# apollo510 register map
Vendor: Ambiq Micro; Series: Apollo; File version: 1.0
CPU: CM55 r1p1, little endian, MPU, FPU, double-precision FPU, DSP, I-cache, D-cache, VTOR, ITCM, DTCM, 4 interrupt priority bits, 0 interrupts, 8 SAU regions
Registers are 32-bit, read-write, reset 0x0 unless marked. A register's access mark holds for its fields unless they carry their own. Offsets are from the block's base; [hi:lo] are bit positions; {n}, {i} and the like mark numbered series; 'fields as' and 'values as' point back to an identical list.

## MCUCTRL (part 2 of 2) — MCU Miscellaneous Control Logic
Base 0x40020000
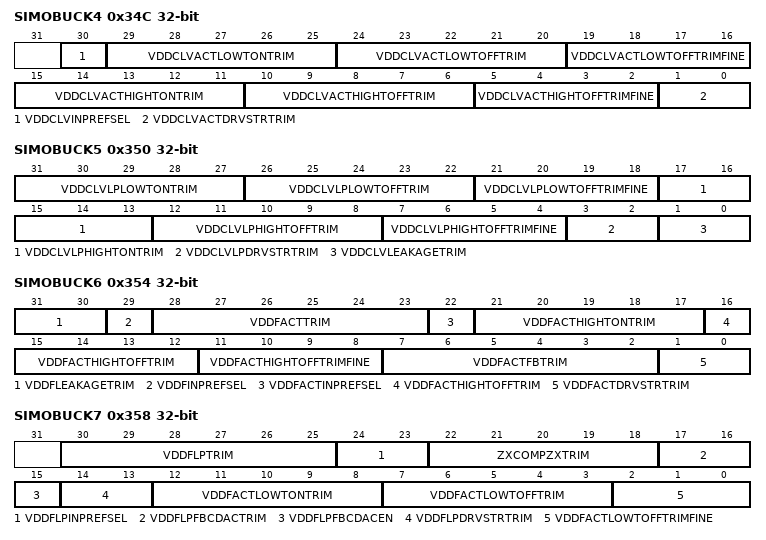
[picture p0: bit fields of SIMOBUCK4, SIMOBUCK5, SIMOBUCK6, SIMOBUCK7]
0x34C SIMOBUCK4 — SIMO Buck Muxed VDDC LV Active Sequence Trim Control
  [30] VDDCLVINPREFSEL — DEPRECATED
  [29:25] VDDCLVACTLOWTONTRIM — VDDC LV active low ton trim control for Buck sequence.
  [24:20] VDDCLVACTLOWTOFFTRIM — VDDC LV active low trim control for a 500 MHz clock inside the simobuck analog design.
  [19:16] VDDCLVACTLOWTOFFTRIMFINE — DEPRECATED.
  [15:11] VDDCLVACTHIGHTONTRIM — VDDC LV active high ton trim control for Buck sequence.
  [10:6] VDDCLVACTHIGHTOFFTRIM — VDDC LV active high toff trim control for Buck sequence.
  [5:2] VDDCLVACTHIGHTOFFTRIMFINE — DEPRECATED.
  [1:0] VDDCLVACTDRVSTRTRIM — VDDC LV active trim control for drive strength.
0x350 SIMOBUCK5 — SIMO Buck Muxed VDDC LV Low PowerSequence Trim Control
  [31:27] VDDCLVLPLOWTONTRIM — VDDC LV low power high ton trim control for Buck sequence.
  [26:22] VDDCLVLPLOWTOFFTRIM — VDDC LV low power low toff trim control for Buck sequence.
  [21:18] VDDCLVLPLOWTOFFTRIMFINE — DEPRECATED.
  [17:13] VDDCLVLPHIGHTONTRIM — VDDC LV low power high ton trim control for Buck sequence.
  [12:8] VDDCLVLPHIGHTOFFTRIM — VDDC LV low power high toff trim control for Buck sequence.
  [7:4] VDDCLVLPHIGHTOFFTRIMFINE — DEPRECATED.
  [3:2] VDDCLVLPDRVSTRTRIM — VDDC LV low power trim control for drive strength.
  [1:0] VDDCLVLEAKAGETRIM — DEPRECATED
0x354 SIMOBUCK6 — SIMO Buck Muxed VDDF Active Sequence Trim Control
  [31:30] VDDFLEAKAGETRIM — DEPRECATED
  [29] VDDFINPREFSEL — DEPRECATED
  [28:23] VDDFACTTRIM — VDDF active trim.
  [22] VDDFACTINPREFSEL — DEPRECATED
  [21:17] VDDFACTHIGHTONTRIM — VDDF active high ton trim control for Buck sequence.
  [16:12] VDDFACTHIGHTOFFTRIM — VDDF active high toff trim control for Buck sequence.
  [11:8] VDDFACTHIGHTOFFTRIMFINE — DEPRECATED.
  [7:2] VDDFACTFBTRIM — DEPRECATED
  [1:0] VDDFACTDRVSTRTRIM — VDDF active high toff trim for drive strength.
0x358 SIMOBUCK7 — SIMO Buck Muxed VDDF active Sequence Trim Control
  [30:25] VDDFLPTRIM — VDDF low power trim.
  [24:23] VDDFLPINPREFSEL — DEPRECATED
  [22:18] ZXCOMPZXTRIM — Zxcomp trim. Feedthrough to analog.
  [17:16] VDDFLPFBCDACTRIM — DEPRECATED
  [15] VDDFLPFBCDACEN — DEPRECATED
  [14:13] VDDFLPDRVSTRTRIM — VDDF active trim control for drive strength.
  [12:8] VDDFACTLOWTONTRIM — VDDF active low ton trim control for Buck sequence.
  [7:3] VDDFACTLOWTOFFTRIM — VDDF active low toff trim control for Buck sequence.
  [2:0] VDDFACTLOWTOFFTRIMFINE — DEPRECATED.
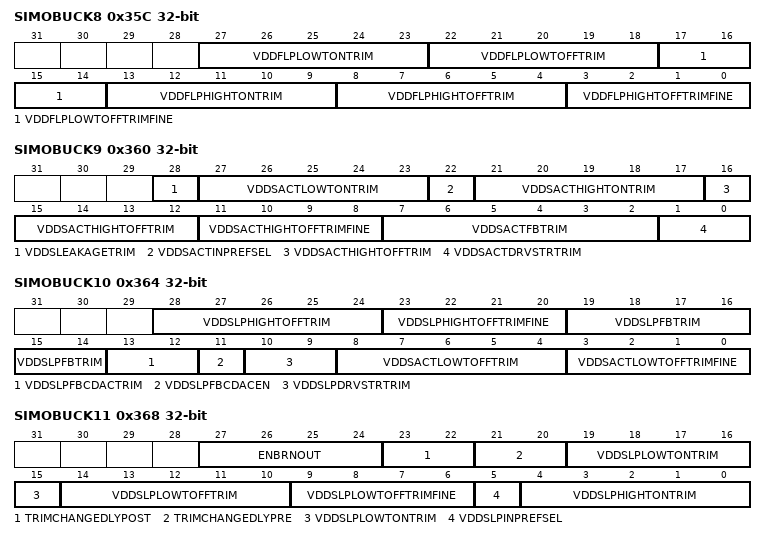
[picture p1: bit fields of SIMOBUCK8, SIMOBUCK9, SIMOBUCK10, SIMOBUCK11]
0x35C SIMOBUCK8 — SIMO Buck Muxed VDDF Low Power Sequence Trim Control
  [27:23] VDDFLPLOWTONTRIM — VDDF low power low ton trim control for Buck sequence.
  [22:18] VDDFLPLOWTOFFTRIM — VDDF low power low toff trim control for Buck sequence.
  [17:14] VDDFLPLOWTOFFTRIMFINE — DEPRECATED.
  [13:9] VDDFLPHIGHTONTRIM — VDDF low power high ton trim control for Buck sequence.
  [8:4] VDDFLPHIGHTOFFTRIM — VDDF low power high toff trim control for Buck sequence.
  [3:0] VDDFLPHIGHTOFFTRIMFINE — DEPRECATED.
0x360 SIMOBUCK9 — SIMO Buck Muxed VDDS Active Sequence Trim Control
  [28] VDDSLEAKAGETRIM — DEPRECATED
  [27:23] VDDSACTLOWTONTRIM — VDDS active low ton trim control for Buck sequence.
  [22] VDDSACTINPREFSEL — DEPRECATED
  [21:17] VDDSACTHIGHTONTRIM — VDDS active high ton trim control for Buck sequence.
  [16:12] VDDSACTHIGHTOFFTRIM — VDDS active high toff trim control for Buck sequence.
  [11:8] VDDSACTHIGHTOFFTRIMFINE — DEPRECATED.
  [7:2] VDDSACTFBTRIM — DEPRECATED
  [1:0] VDDSACTDRVSTRTRIM — simobuck_vdds_act_drvstr_trim
0x364 SIMOBUCK10 — SIMO Buck Muxed VDDS active Sequence Trim Control
  [28:24] VDDSLPHIGHTOFFTRIM — VDDS low power high toff trim control for a Buck sequence.
  [23:20] VDDSLPHIGHTOFFTRIMFINE — DEPRECATED.
  [19:14] VDDSLPFBTRIM — DEPRECATED
  [13:12] VDDSLPFBCDACTRIM — DEPRECATED
  [11] VDDSLPFBCDACEN — DEPRECATED
  [10:9] VDDSLPDRVSTRTRIM — VDDS low power trim control for drive strength.
  [8:4] VDDSACTLOWTOFFTRIM — VDDS active low toff trim control for Buck sequence.
  [3:0] VDDSACTLOWTOFFTRIMFINE — DEPRECATED.
0x368 SIMOBUCK11 — SIMO Buck Muxed Sequence Trim Control
  [27:24] ENBRNOUT — Enable each individual rail counter.
  [23:22] TRIMCHANGEDLYPOST — Delay used on the trims valid assertion after trims are changed.
  [21:20] TRIMCHANGEDLYPRE — Delay used on the trims valid de-assertion before trims are changed.
  [19:15] VDDSLPLOWTONTRIM — VDDS low power low ton trim control for a Buck sequence.
  [14:10] VDDSLPLOWTOFFTRIM — VDDS low power low toff trim control for a Buck sequence.
  [9:6] VDDSLPLOWTOFFTRIMFINE — DEPRECATED.
  [5] VDDSLPINPREFSEL — DEPRECATED
  [4:0] VDDSLPHIGHTONTRIM — VDDS low power high ton trim control for a Buck sequence.
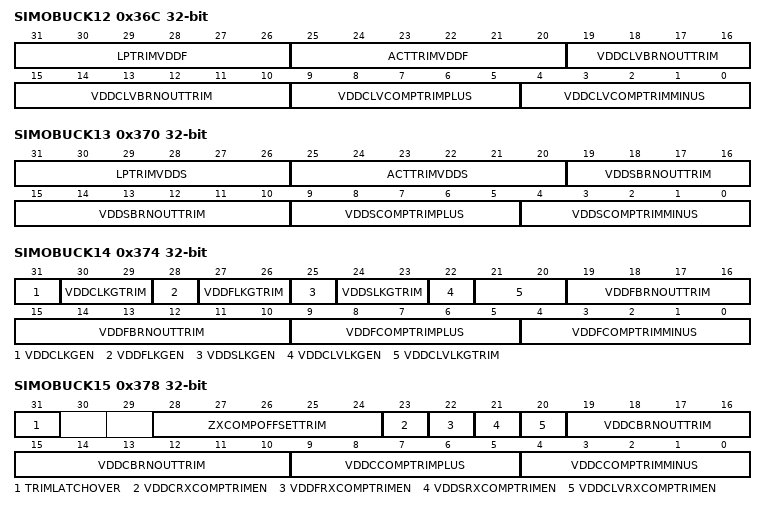
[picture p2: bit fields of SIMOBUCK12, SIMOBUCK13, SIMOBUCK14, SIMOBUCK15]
0x36C SIMOBUCK12 — SIMO Buck Compare, Brown out, Active, Low power Trim Control
  [31:26] LPTRIMVDDF — Low power VDDF trim.
  [25:20] ACTTRIMVDDF — Active VDDF trim.
  [19:10] VDDCLVBRNOUTTRIM — Digital brown out max counter value for VDDC LV rail.
  [9:5] VDDCLVCOMPTRIMPLUS — Static trim to allow separation when low power GT active rail.
  [4:0] VDDCLVCOMPTRIMMINUS — Static trim to allow separation between low power and active rail.
0x370 SIMOBUCK13 — SIMO Buck Compare, Brown out, Active, Low power Trim Control
  [31:26] LPTRIMVDDS — Low power VDDS trim.
  [25:20] ACTTRIMVDDS — Active VDDS trim.
  [19:10] VDDSBRNOUTTRIM — Digital brown out max counter value for VDDS rail.
  [9:5] VDDSCOMPTRIMPLUS — Static trim to allow separation when low power GT active rail.
  [4:0] VDDSCOMPTRIMMINUS — Static trim to allow separation between low power and active rail.
0x374 SIMOBUCK14 — SIMO Buck Compare, Brown out, Active, Low power and Leakage Trim Control
  [31] VDDCLKGEN — Leakage vddc rail enable. Set before simobuck comes up.
  [30:29] VDDCLKGTRIM — Leakage trim for vddc.
  [28] VDDFLKGEN — Leakage vddf rail enable. Set before simobuck comes up.
  [27:26] VDDFLKGTRIM — Leakage trim for vddf.
  [25] VDDSLKGEN — Leakage vdds rail enable. Set before simobuck comes up.
  [24:23] VDDSLKGTRIM — Leakage trim for vdds.
  [22] VDDCLVLKGEN — Leakage vddc lv rail enable. Set before simobuck comes up.
  [21:20] VDDCLVLKGTRIM — Leakage trim for vddc lv.
  [19:10] VDDFBRNOUTTRIM — Digital Brown out max counter value for VDDF rail.
  [9:5] VDDFCOMPTRIMPLUS — Static trim to allow separation when low power GT active rail.
  [4:0] VDDFCOMPTRIMMINUS — Static trim to allow separation between low power and active rail.
0x378 SIMOBUCK15 — SIMO Buck Compare, Brown out, Active and Low power Trim Control
  [31] TRIMLATCHOVER — Override / Bypass the simobuck trim latch to enable on-the-fly trimming for VDDF and VDDS active and LP trims
  [28:24] ZXCOMPOFFSETTRIM — Zxcomp offset trim. Feedthrough to analog.
  [23] VDDCRXCOMPTRIMEN — Enable the VDDC rail. If not enabled, the rail will not be regulated. This must be done before simobuck comes up.
  [22] VDDFRXCOMPTRIMEN — Enable the VDDF rail. If not enabled, the rail will not be regulated. This must be done before simobuck comes up.
  [21] VDDSRXCOMPTRIMEN — Enable the VDDS rail. If not enabled, the rail will not be regulated. This must be done before simobuck comes up.
  [20] VDDCLVRXCOMPTRIMEN — Enable the VDDC LV rail. If not enabled, the rail will not be regulated. This must be done before simobuck comes up.
  [19:10] VDDCBRNOUTTRIM — Digital brown out max counter value for VDDC rail.
  [9:5] VDDCCOMPTRIMPLUS — Static trim to allow separation when low power GT active rail.
  [4:0] VDDCCOMPTRIMMINUS — Static trim to allow separation between low power and active rail.
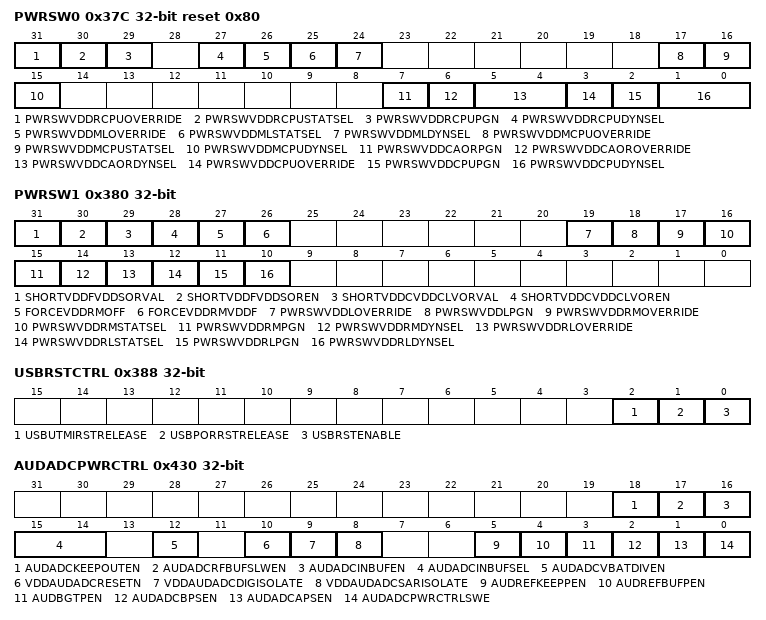
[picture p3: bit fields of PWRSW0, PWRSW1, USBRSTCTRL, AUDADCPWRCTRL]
0x37C PWRSW0 reset 0x80 — PWRSW Control 0
  [31] PWRSWVDDRCPUOVERRIDE — override enable for pwrsw_vddrcpu_dynsel and pgn
  [30] PWRSWVDDRCPUSTATSEL — VDDRCPU power switch static select
    1=VDDFLP (Select VDDFLP rail); 0=VDDS (Select VDDS rail)
  [29] PWRSWVDDRCPUPGN — override value for pwrsw_vddrcpu_pgn
  [27] PWRSWVDDRCPUDYNSEL — override value for pwrsw_vddrcpu_dynsel
  [26] PWRSWVDDMLOVERRIDE — override enable for pwrsw_vddml_dynsel
  [25] PWRSWVDDMLSTATSEL — VDDML power switch static select
    0=VDDC (Select VDDC rail); 1=VDDF (Select VDDF rail)
  [24] PWRSWVDDMLDYNSEL — override value for pwrsw_vddml_dynsel
  [17] PWRSWVDDMCPUOVERRIDE — override enable for pwrsw_vddmcpu_dynsel
  [16] PWRSWVDDMCPUSTATSEL — VDDMCPU power switch static select
    0=VDDC (Select VDDC rail); 1=VDDF (Select VDDF rail)
  [15] PWRSWVDDMCPUDYNSEL — override value for pwrsw_vddmcpu_dynsel
  [7] PWRSWVDDCAORPGN — override enable for pwrsw_vddcaor_pgn
  [6] PWRSWVDDCAOROVERRIDE — override enable for pwrsw_vddcaor_dynsel
  [5:4] PWRSWVDDCAORDYNSEL — override value for pwrsw_vddcaor_dynsel
  [3] PWRSWVDDCPUOVERRIDE — override enable for pwrsw_vddcpu_dynsel and pgn
  [2] PWRSWVDDCPUPGN — override value for pwrsw_vddcpu_pgn
  [1:0] PWRSWVDDCPUDYNSEL — override value for pwrsw_vddcpu_dynsel
0x380 PWRSW1 — PWRSW Control 1
  [31] SHORTVDDFVDDSORVAL — pwrsw short override value for vddf/vdds
  [30] SHORTVDDFVDDSOREN — pwrsw short override select for vddf/vdds
  [29] SHORTVDDCVDDCLVORVAL — pwrsw short override value for vddc/vddclv
  [28] SHORTVDDCVDDCLVOREN — pwrsw short override select for vddc/vddclv
  [27] FORCEVDDRMOFF — Setting this bit forces VDDRM to be open when Flash is off. This is valid for only normal operational mode (i.e. without overrides).
  [26] FORCEVDDRMVDDF — Setting this bit selects VDDF for VDDRM when Flash is off. This is valid for only normal operational mode (i.e. without overrides).
  [19] PWRSWVDDLOVERRIDE — override enable for pwrsw_vddl_pgn
  [18] PWRSWVDDLPGN — override value for pwrsw_vddl_pgn
  [17] PWRSWVDDRMOVERRIDE — override enable for pwrsw_vddrm_dynsel and pgn
  [16] PWRSWVDDRMSTATSEL — VDDRM power switch static select
    1=VDDFLP (Select VDDFLP rail); 0=VDDS (Select VDDS rail)
  [15] PWRSWVDDRMPGN — override value for pwrsw_vddrm_pgn
  [14] PWRSWVDDRMDYNSEL — override value for pwrsw_vddrm_dynsel
  [13] PWRSWVDDRLOVERRIDE — override enable for pwrsw_vddrl_dynsel and pgn
  [12] PWRSWVDDRLSTATSEL — VDDRL power switch static select
    1=VDDFLP (Select VDDFLP rail); 0=VDDS (Select VDDS rail)
  [11] PWRSWVDDRLPGN — override value for pwrsw_vddrl_pgn
  [10] PWRSWVDDRLDYNSEL — override value for pwrsw_vddrl_dynsel
0x388 USBRSTCTRL — USB Reset Startup Control
  [2] USBUTMIRSTRELEASE — Set this bit to '1' after USB power domain is up. This will release the reset override condition
  [1] USBPORRSTRELEASE — Set this bit to '1' after USB power domain is up. This will release the reset override condition
  [0] USBRSTENABLE — This bit enables this register control. If set to '1', the reset release bits will be active. If set to '0', this register is not controlling the USB override bits.
{0x3A8+4i} FLASHWPROT{i} (i=0..3) — These bits write-protect flash in 16KB chunks, but cpu still can excute from that that memory.
  [31:0] FW{i}BITS — Write protect flash {0x0+0x80000*i} - {0x7FFFF+0x80000*i}. Each bit provides write protection for 16KB chunks of flash data space. Bits are cleared by writing a 1 to the bit. When read, 0 indicates the region is protected. Bits are sticky (can be set when PROTLOCK is 1, but only cleared by reset)
{0x3B8+4i} FLASHRPROT{i} (i=0..3) — These bits read-protect flash in 16KB chunks, but cpu still can excute from that that memory.
  [31:0] FR{i}BITS — Copy (read) protect flash {0x0+0x80000*i} - {0x7FFFF+0x80000*i}. Each bit provides read protection for 16KB chunks of flash. Bits are cleared by writing a 1 to the bit. When read, 0 indicates the region is protected. Bits are sticky (can be set when PROTLOCK is 1, but only cleared by reset)
{0x3C8+4i} SRAMWPROT{i} (i=0..5) — These bits write-protect system SRAM from non-cpu access in 16KB chunks.
  [31:0] SRAMWPROT{i} — Write protect SRAM from non-cpu access. Each bit provides write protection for an 16KB region of memory. When set to 1, the region will be protected from non-cpu writes, when set to 0, DMA may write the region.
{0x3F0+4i} SRAMRPROT{i} (i=0..5) — These bits read-protect system SRAM from non-cpu access in 16KB chunks.
  [31:0] SRAMRPROT{i} — Read protect SRAM from non-cpu access. Each bit provides write protection for an 16KB region of memory. When set to 1, the region will be protected from non-cpu reads, when set to 0, DMA may read the region.
0x430 AUDADCPWRCTRL — Audio ADC Power Control
  [18] AUDADCKEEPOUTEN — Audio ADC reference keeper out en
  [17] AUDADCRFBUFSLWEN — Audio ADC reference buffer slew enable
  [16] AUDADCINBUFEN — Audio ADC Input Buffer Power Enable ( if the AUDADCPWRCTRLSWE bit is set )
  [15:14] AUDADCINBUFSEL — Audio ADC input buffer mux select
  [12] AUDADCVBATDIVEN — Audio ADC VBAT DIV Power Enable ( if the AUDADCPWRCTRLSWE bit is set )
  [10] VDDAUDADCRESETN — RESETN signal for Power Switched SAR and Digital Controller (when global power switch is off and if the AUDADCPWRCTRLSWE bit is set)
    0=ASSERT (Resetn is asserted); 1=DEASSERT (Resetn is de-asserted)
  [9] VDDAUDADCDIGISOLATE — ISOLATE signal for audio ADC Digital Contoller ( when AUDADCAPSEN is switched off and if the AUDADCPWRCTRLSWE bit is set)
    0=DIS (No Isolation); 1=EN (Isolate)
  [8] VDDAUDADCSARISOLATE — ISOLATE signal for Power Switched SAR ( when AUDADCBPSEN is switched off )
    0=DIS (No Isolation); 1=EN (Isolate)
  [5] AUDREFKEEPPEN — Reference Buffer Keeper Power Switch Enable
    0=DIS (Reference Buffer Keeper Power Switch disable.); 1=EN (Reference Buffer Keeper Power Switch enable.)
  [4] AUDREFBUFPEN — Reference Buffer Power Switch Enable
    0=DIS (Reference Buffer Power Switch disable.); 1=EN (Reference Buffer Power Switch enable.)
  [3] AUDBGTPEN — Bandgap and Temperature Sensor Power Switch Enable
    0=DIS (Bandgap and temperature sensor disable.); 1=EN (Bandgap and temperature sensor enable.)
  [2] AUDADCBPSEN — Enable the Analog, IO and SAR Digital logic Power Switch on when set to 1 if the AUDADCPWRCTRLSWE bit is set.
    0=DIS (AUDADC power switch software power disable.); 1=EN (AUDADC power switch software power enable.)
  [1] AUDADCAPSEN — Enable the Global audio ADC Power Switch on when set to 1 if the AUDADCPWRCTRLSWE bit is set.
    values as AUDADCBPSEN
  [0] AUDADCPWRCTRLSWE — Audio ADC Power Control Software Override Enable
    0=OVERRIDE_DIS (Audio ADC temperature sensor and bandgap Software Override Disable.); 1=OVERRIDE_EN (Audio ADC temperature sensor and bandgap Software Override Enable.)
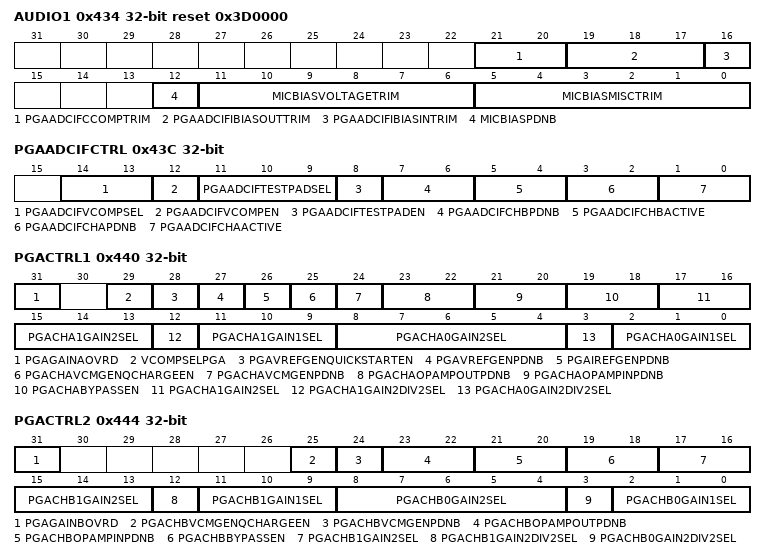
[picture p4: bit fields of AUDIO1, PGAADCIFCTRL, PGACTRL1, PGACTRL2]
0x434 AUDIO1 reset 0x3D0000 — Audio trims 1
  [21:20] PGAADCIFCCOMPTRIM, [19:17] PGAADCIFIBIASOUTTRIM, [16] PGAADCIFIBIASINTRIM, [12] MICBIASPDNB, [11:6] MICBIASVOLTAGETRIM, [5:0] MICBIASMISCTRIM
0x43C PGAADCIFCTRL — PGA ADCIF control
  [14:13] PGAADCIFVCOMPSEL, [12] PGAADCIFVCOMPEN, [11:9] PGAADCIFTESTPADSEL, [8] PGAADCIFTESTPADEN, [7:6] PGAADCIFCHBPDNB, [5:4] PGAADCIFCHBACTIVE, [3:2] PGAADCIFCHAPDNB, [1:0] PGAADCIFCHAACTIVE
0x440 PGACTRL1 — PGA control 1
  [31] PGAGAINAOVRD — Apply BYPASS and GAIN bits from this register (for channel A) instead of automatically via audio ADC. Note that audio ADC FIFO meta data will not reflect dB gain as used when configuring audio ADC.
  [29] VCOMPSELPGA — d2a_vcomp_sel_pga_vddh
  [28] PGAVREFGENQUICKSTARTEN — d2a_pga_vrefgen_quickstart_en_vddh
  [27] PGAVREFGENPDNB — d2a_pga_vrefgen_pdnb_vddh
  [26] PGAIREFGENPDNB — d2a_pga_irefgen_pdnb_vddh
  [25] PGACHAVCMGENQCHARGEEN — d2a_pga_chA_vcmgen_qcharge_en_vddh
  [24] PGACHAVCMGENPDNB — d2a_pga_chA_vcmgen_pdnb_vddh
  [23:22] PGACHAOPAMPOUTPDNB — d2a_pga_chA_opamp_out_pdnb_vddh
  [21:20] PGACHAOPAMPINPDNB — d2a_pga_chA_opamp_in_pdnb_vddh
  [19:18] PGACHABYPASSEN — d2a_pga_chA_bypass_en_vddh
  [17:13] PGACHA1GAIN2SEL — d2a_pga_chA1_gain2_sel_vddh
  [12] PGACHA1GAIN2DIV2SEL — d2a_pga_chA1_gain2_div2_sel_vddh
  [11:9] PGACHA1GAIN1SEL — d2a_pga_chA1_gain1_sel_vddh
  [8:4] PGACHA0GAIN2SEL — d2a_pga_chA0_gain2_sel_vddh
  [3] PGACHA0GAIN2DIV2SEL — d2a_pga_chA0_gain2_div2_sel_vddh
  [2:0] PGACHA0GAIN1SEL — d2a_pga_chA0_gain1_sel_vddh
0x444 PGACTRL2 — PGA control 2
  [31] PGAGAINBOVRD — Apply BYPASS and GAIN bits from this register (for channel B) instead of automatically via audio ADC. Note that audio ADC FIFO meta data will not reflect dB gain as used when configuring audio ADC.
  [25] PGACHBVCMGENQCHARGEEN — d2a_pga_chB_vcmgen_qcharge_en_vddh
  [24] PGACHBVCMGENPDNB — d2a_pga_chB_vcmgen_pdnb_vddh
  [23:22] PGACHBOPAMPOUTPDNB — d2a_pga_chB_opamp_out_pdnb_vddh
  [21:20] PGACHBOPAMPINPDNB — d2a_pga_chB_opamp_in_pdnb_vddh
  [19:18] PGACHBBYPASSEN — d2a_pga_chB_bypass_en_vddh
  [17:13] PGACHB1GAIN2SEL — d2a_pga_chB1_gain2_sel_vddh
  [12] PGACHB1GAIN2DIV2SEL — d2a_pga_chB1_gain2_div2_sel_vddh
  [11:9] PGACHB1GAIN1SEL — d2a_pga_chB1_gain1_sel_vddh
  [8:4] PGACHB0GAIN2SEL — d2a_pga_chB0_gain2_sel_vddh
  [3] PGACHB0GAIN2DIV2SEL — d2a_pga_chB0_gain2_div2_sel_vddh
  [2:0] PGACHB0GAIN1SEL — d2a_pga_chB0_gain1_sel_vddh
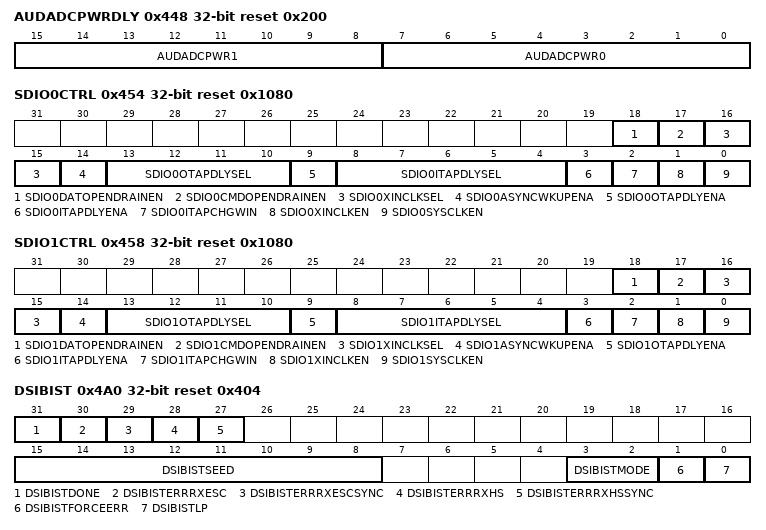
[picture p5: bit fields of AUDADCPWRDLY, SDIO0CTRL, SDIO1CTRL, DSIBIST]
0x448 AUDADCPWRDLY reset 0x200 — Audio ADC Power Up Delay Control
  [15:8] AUDADCPWR1 — ADC Reference Keeper enable delay in 16 ADC CLK increments for ADC_CLKSEL = 0x1, 8 ADC CLOCK increments for ADC_CLKSEL = 0x2.
  [7:0] AUDADCPWR0 — ADC Reference Buffer Power Enable delay in 64 ADC CLK increments for ADC_CLKSEL = 0x1, 32 ADC CLOCK increments for ADC_CLKSEL = 0x2.
0x454 SDIO0CTRL reset 0x1080 — SDIO0/eMMC Control
  [18] SDIO0DATOPENDRAINEN — SDIO0 DAT line configured as open-drian. 0: Push-pull mode, 1: Open-drain mode
  [17] SDIO0CMDOPENDRAINEN — SDIO0 CMD line configured as open-drian. 0: Push-pull mode, 1: Open-drain mode
  [16:15] SDIO0XINCLKSEL — Select clock source for SDIO0 xin_clk.
    0=HFRC_96MHz (96MHz sourced from the HFRC); 1=HFRC_48MHz (48MHz sourced from the HFRC); 2=HFRC_24MHz (24MHz sourced from the HFRC)
  [14] SDIO0ASYNCWKUPENA — SDIO0 asynchronous wakeup mode. 0: Synchronous wakeup mode, 1: Asynchronous wakeup mode
  [13:10] SDIO0OTAPDLYSEL — Selects one of the 16 Taps on the sdcard_clk. This is effective only when otapdlyena is asserted.
  [9] SDIO0OTAPDLYENA — Used to enable the selective Tap delay on the sdcard_clk so as to generate the delayed sdcard_clk. This is used to latch the CMD/DAT outputs to generate delay on them w.r.t CLK going out. This signal along with otapdlysel[3:0] selects the amount of delay to be inserted on the Clock line. This signal should not be asserted when operating in DS mode.
  [8:4] SDIO0ITAPDLYSEL — Selects one of the 32 Taps on the rxclk_in line. This is effective only when itapdlyena is asserted and Tuning is not enabled.
  [3] SDIO0ITAPDLYENA — Used to enable selective Tap delay line on the Looped back SD Clock (rxclk_in). This signal along with the itapdlysel[4:0] selects the the amount of delay to be inserted on the line. When Tuning is enabled (for SDR104 and optionally for SDR50), this signal is ignored and internalcontrols are used instead. This should not be asserted when operating in DS mode.
  [2] SDIO0ITAPCHGWIN — This is used to gate the output of the Tap Delay lines so as to avoid glithches being propagated into the Core. This signal should be asserted few clocks before the itapdlysel changes and should be asserted for few clocks after.
  [1] SDIO0XINCLKEN — SDIO0 serial clock source enable.
  [0] SDIO0SYSCLKEN — SDIO0 system clock enable.
0x458 SDIO1CTRL reset 0x1080 — SDIO1/eMMC Control
  [18] SDIO1DATOPENDRAINEN — SDIO1 DAT line configured as open-drian. 0: Push-pull mode, 1: Open-drain mode
  [17] SDIO1CMDOPENDRAINEN — SDIO1 CMD line configured as open-drian. 0: Push-pull mode, 1: Open-drain mode
  [16:15] SDIO1XINCLKSEL — Select clock source for SDIO1 xin_clk.
    values as SDIO0CTRL.SDIO0XINCLKSEL
  [14] SDIO1ASYNCWKUPENA — SDIO1 asynchronous wakeup mode. 0: Synchronous wakeup mode, 1: Asynchronous wakeup mode
  [13:10] SDIO1OTAPDLYSEL — Selects one of the 16 Taps on the sdcard_clk. This is effective only when otapdlyena is asserted.
  [9] SDIO1OTAPDLYENA — Used to enable the selective Tap delay on the sdcard_clk so as to generate the delayed sdcard_clk. This is used to latch the CMD/DAT outputs to generate delay on them w.r.t CLK going out. This signal along with otapdlysel[3:0] selects the amount of delay to be inserted on the Clock line. This signal should not be asserted when operating in DS mode.
  [8:4] SDIO1ITAPDLYSEL — Selects one of the 32 Taps on the rxclk_in line. This is effective only when itapdlyena is asserted and Tuning is not enabled.
  [3] SDIO1ITAPDLYENA — Used to enable selective Tap delay line on the Looped back SD Clock (rxclk_in). This signal along with the itapdlysel[4:0] selects the the amount of delay to be inserted on the line. When Tuning is enabled (for SDR104 and optionally for SDR50), this signal is ignored and internalcontrols are used instead. This should not be asserted when operating in DS mode.
  [2] SDIO1ITAPCHGWIN — This is used to gate the output of the Tap Delay lines so as to avoid glithches being propagated into the Core. This signal should be asserted few clocks before the itapdlysel changes and should be asserted for few clocks after.
  [1] SDIO1XINCLKEN — SDIO1 serial clock source enable.
  [0] SDIO1SYSCLKEN — SDIO1 system clock enable.
0x45C PDMCTRL reset 0x1 — PDM Control
  [0] PDMGLOBALEN — PDM global enable to allow all PDMs to have synchronized interface clocks and FIFO sampling.
0x4A0 DSIBIST reset 0x404 — DPHY BIST register for the Analog testing
  [31] DSIBISTDONE — Status of the BIST engine, indicates the completion as well as error conditions.
  [30] DSIBISTERRRXESC — Indicates the normal error conditions in LP mode. Also indicates the RxClkEsc mode error.
  [29] DSIBISTERRRXESCSYNC — Indicates the sync error conditions in LP mode.
  [28] DSIBISTERRRXHS — Indicates the normal error conditions in HS mode.
  [27] DSIBISTERRRXHSSYNC — Indicates the sync error conditions in HS mode.
  [15:8] DSIBISTSEED — bist_seed in hardware
  [3:2] DSIBISTMODE — {bist_en_esc_lp, bist_en_esc_hs} in hardware.
    1=HSMODE; 2=LPMODE; 3=RXCLKESCMODE
  [1] DSIBISTFORCEERR — bist_force_error in hardware
  [0] DSIBISTLP — To enable the BIST this bit (dln_loop_back in hardware) needs to be set to 1. This signal internally asserts the clock for the BIST modules.
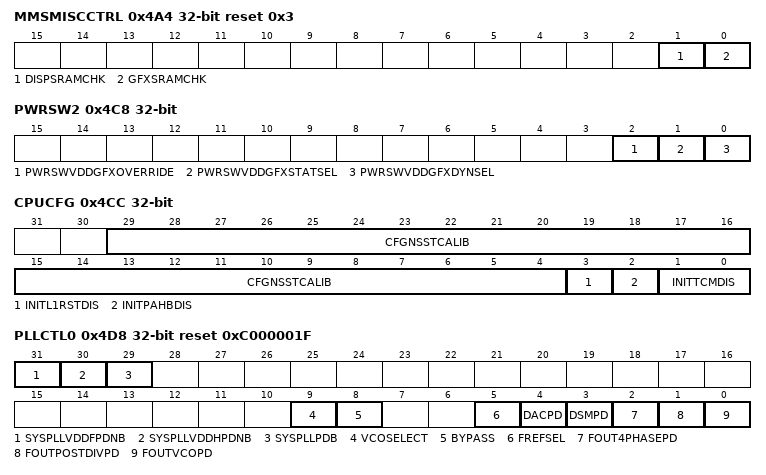
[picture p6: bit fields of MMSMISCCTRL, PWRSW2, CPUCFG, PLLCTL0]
0x4A4 MMSMISCCTRL reset 0x3 — MM Sytem Miscellaneous Control
  [1] DISPSRAMCHK — Control bit for the sram power domain checking in DC.
    0=DIS (Disable sram power domain checking.); 1=EN (Enable sram power domain checking)
  [0] GFXSRAMCHK — Control bit for the sram power domain checking in GFX.
    values as DISPSRAMCHK
{0x498+4i} FLASHWPROT{i} (i=4..6) — These bits write-protect flash in 16KB chunks, but cpu still can excute from that that memory.
  fields as FLASHWPROT0
0x4B4 FLASHWPROT7 — These bits write-protect flash in 16KB chunks, but cpu still can excute from that that memory.
  [31:0] FW7BITS — Write protect flash 0x00380000 - 0x004FFFFF. Each bit provides write protection for 16KB chunks of flash data space. Bits are cleared by writing a 1 to the bit. When read, 0 indicates the region is protected. Bits are sticky (can be set when PROTLOCK is 1, but only cleared by reset)
{0x4A8+4i} FLASHRPROT{i} (i=4..7) — These bits read-protect flash in 16KB chunks, but cpu still can excute from that that memory.
  fields as FLASHRPROT0
0x4C8 PWRSW2 — PWRSW Control 2
  [2] PWRSWVDDGFXOVERRIDE — override enable for pwrsw_vddgfx_dynsel and pgn
  [1] PWRSWVDDGFXSTATSEL — override value for pwrsw_vddgfx_statsel
  [0] PWRSWVDDGFXDYNSEL — override value for pwrsw_vddgfx_dynsel
0x4CC CPUCFG — CPU config
  [29:4] CFGNSSTCALIB — CFGNSST calib value
  [3] INITL1RSTDIS — Init L1 reset diable
  [2] INITPAHBDIS — InitPAHB disable
  [1:0] INITTCMDIS — INIT TCM disable
0x4D8 PLLCTL0 reset 0xC000001F — This register controls power down and enable for various features of the system PLL
  [31] SYSPLLVDDFPDNB — System PLL VDDF enable
    0=ENABLE (VDDF power up); 1=DISABLE (VDDF disable)
  [30] SYSPLLVDDHPDNB — System PLL VDDH enable
    0=ENABLE (VDDH power up); 1=DISABLE (VDDH disable)
  [29] SYSPLLPDB — System PLL enable. When the PLL is enabled, SW must ensure that the PLL receives adequate current by forcing the LDO to be in active mode: SIMOBUCKACTIVE = 1 (in BUCK mode), MEMLDOACTIVE = 1 (in LDO mode).
    0=DISABLE (PLL power down); 1=ENABLE (PLL enable)
  [9] VCOSELECT — System PLL VCO range select, connected to PLL pin VCOSEL
    0=VCOLO (VCO operates in the range 60MHz - 240MHz); 1=VCOHI (VCO operates in the range 240MHz - 960MHz)
  [8] BYPASS — System PLL bypass, connected to PLL pin BYPASS
    0=NORMAL (Normal operation); 1=BYPASS (FREF is bypassed to FOUTPOSTDIV)
  [5] FREFSEL — System PLL reference clock select, connected to PLL pin FREF
    0=XTAL32MHz (Select high frequency crystal oscillator output (e.g. 32 MHz)); 1=EXTREFCLK (Select external reference clock (from GPIO))
  [4] DACPD — System PLL noise canceling DAC power down, connected to PLL pin DACPD
    0=ACTIVE (Noise canceling DAC is active); 1=POWERDOWN (Power down noise canceling DAC (test mode only))
  [3] DSMPD — System PLL DSM (delta-sigma modulator) power down, connected to PLL pin DSMPD
    0=ACTIVE (DSM is active); 1=POWERDOWN (DSM is powered down)
  [2] FOUT4PHASEPD — System PLL 4-phase clock generator power down, connected to PLL pin FOUT4PHASEPD
    0=ACTIVE (Four phase clock generator and outputs are enabled); 1=POWERDOWN (Four phase clock generator and outputs are disabled)
  [1] FOUTPOSTDIVPD — System PLL post divider power down, connected to PLL pin FOUTPOSTDIVPD. Must enable when using 4-phase outputs
    0=ACTIVE (Post divider enabled); 1=POWERDOWN (Post divider disabled)
  [0] FOUTVCOPD — System PLL VCO rate output clock power down, connected to PLL pin FOUTVCOPD
    0=ACTIVE (Rate output enabled); 1=POWERDOWN (Rate output disabled)
0x4DC PLLDIV0 — This register sets the fractional portion of the feedback divider when the system PLL is in fractional mode. Refer to the PLLTS22ULPHVLPFRACA datasheet for more details
  [23:0] FRAC — System PLL feedback divide value (fractional portion), connected to PLL pin FRAC[23:0]. Do not change FRAC while the clock is in use as it can make the clock unstable. First disable the clock, change FRAC, and then enable the clock
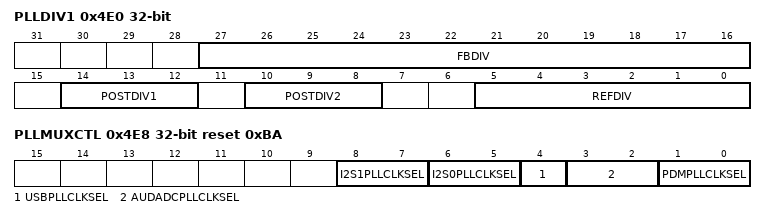
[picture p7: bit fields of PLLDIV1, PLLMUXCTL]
0x4E0 PLLDIV1 — This register sets the integer portion of the feedback divider along with the other dividers in the system PLL. Refer to the PLLTS22ULPHVLPFRACA datasheet for more details
  [27:16] FBDIV — System PLL feedback divide value, connected to PLL pin FBDIV[11:0]. Valid range is 4 to 960 in integer mode, 10 to 96 in fractional mode. Do not change FBDIV while the clock is in use as it can make the clock unstable. First disable the clock, change FBDIV, and then enable the clock
  [14:12] POSTDIV1 — System PLL post divide 1 setting, connected to PLL pin POSTDIV1[2:0]. Valid range is 1 to 7. A setting of 0 will send 1 to the PLL. Total post divide is POSTDIV1*POSTDIV2
  [10:8] POSTDIV2 — System PLL post divide 2 setting, connected to PLL pin POSTDIV2[2:0]. Valid range is 1 to 7. A setting of 0 will send 1 to the PLL. Total post divide is POSTDIV1*POSTDIV2. The value of POSTDIV1 should be maximized before enabling POSTDIV2.
  [5:0] REFDIV — System PLL reference divide value, connnected to PLL pin REFDIV[5:0]. Valid range is 1 to 63. A setting of 0 will send 1 to the PLL
0x4E4 PLLSTAT — This register indicates the system PLL status
  [0] LOCK — System PLL lock signal, connected to PLL pin LOCK. Indicates no cycle slip between the feedback clock and FPFD for 128 consecutive cycles
0x4E8 PLLMUXCTL reset 0xBA — This register selects clock sources for the clocks that may be driven by the system PLL
  [8:7] I2S1PLLCLKSEL — I2S1 PLL clock select
    0=PLLFOUT4 (FOUTPOSTDIV divide by 8 from PLL); 1=PLLFOUT3 (FOUTPOSTDIV divide by 6 from PLL); 2=CLKGEN (I2S1 clock from CLKGEN)
  [6:5] I2S0PLLCLKSEL — I2S0 PLL clock select
    0=PLLFOUT4 (FOUTPOSTDIV divide by 8 from PLL); 1=PLLFOUT3 (FOUTPOSTDIV divide by 6 from PLL); 2=CLKGEN (I2S0 clock from CLKGEN)
  [4] USBPLLCLKSEL — USB PLL clock select
    0=PLL (FOUTPOSTDIV from PLL); 1=CLKGEN (USB PHY clock from CLKGEN)
  [3:2] AUDADCPLLCLKSEL — AUDADC PLL clock select
    0=PLL (FOUTPOSTDIV from PLL); 1=HFRC (48MHz HFRC clock); 2=CLKGEN (AUDADC clock from CLKGEN)
  [1:0] PDMPLLCLKSEL — PDM PLL clock select
    0=PLL (FOUTPOSTDIV from PLL); 1=HFRC (48MHz HFRC clock); 2=CLKGEN (PDM clock from CLKGEN)
